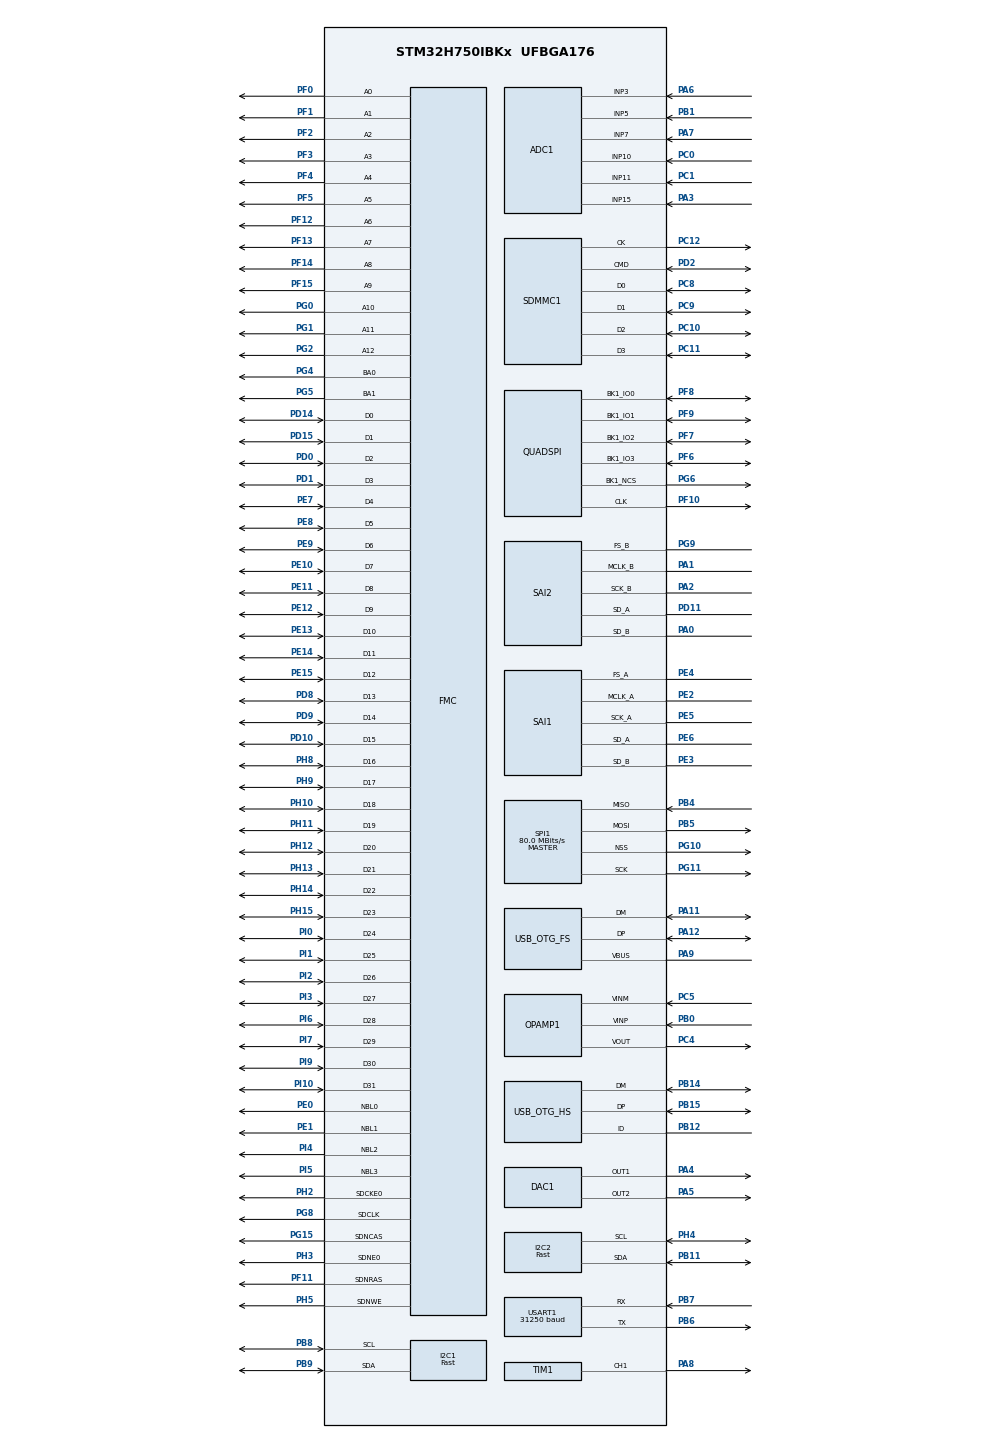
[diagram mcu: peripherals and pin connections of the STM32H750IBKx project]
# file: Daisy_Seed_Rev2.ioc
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ADC1.Channel-1\#ChannelRegularConversion=ADC_CHANNEL_3
ADC1.Channel-2\#ChannelRegularConversion=ADC_CHANNEL_4
ADC1.Channel-3\#ChannelRegularConversion=ADC_CHANNEL_7
ADC1.Channel-4\#ChannelRegularConversion=ADC_CHANNEL_10
ADC1.Channel-5\#ChannelRegularConversion=ADC_CHANNEL_11
ADC1.Channel-6\#ChannelRegularConversion=ADC_CHANNEL_15
ADC1.Channel-7\#ChannelRegularConversion=ADC_CHANNEL_15
ADC1.ClockPrescaler=ADC_CLOCK_ASYNC_DIV32
ADC1.ContinuousConvMode=ENABLE
ADC1.ConversionDataManagement=ADC_CONVERSIONDATA_DMA_CIRCULAR
ADC1.EOCSelection=ADC_EOC_SEQ_CONV
ADC1.NbrOfConversion=7
ADC1.NbrOfConversionFlag=1
ADC1.OffsetNumber-1\#ChannelRegularConversion=ADC_OFFSET_NONE
ADC1.OffsetNumber-2\#ChannelRegularConversion=ADC_OFFSET_NONE
ADC1.OffsetNumber-3\#ChannelRegularConversion=ADC_OFFSET_NONE
ADC1.OffsetNumber-4\#ChannelRegularConversion=ADC_OFFSET_NONE
ADC1.OffsetNumber-5\#ChannelRegularConversion=ADC_OFFSET_NONE
ADC1.OffsetNumber-6\#ChannelRegularConversion=ADC_OFFSET_NONE
ADC1.OffsetNumber-7\#ChannelRegularConversion=ADC_OFFSET_NONE
ADC1.Rank-1\#ChannelRegularConversion=1
ADC1.Rank-2\#ChannelRegularConversion=2
ADC1.Rank-3\#ChannelRegularConversion=3
ADC1.Rank-4\#ChannelRegularConversion=4
ADC1.Rank-5\#ChannelRegularConversion=5
ADC1.Rank-6\#ChannelRegularConversion=6
ADC1.Rank-7\#ChannelRegularConversion=7
ADC1.SamplingTime-1\#ChannelRegularConversion=ADC_SAMPLETIME_32CYCLES_5
ADC1.SamplingTime-2\#ChannelRegularConversion=ADC_SAMPLETIME_32CYCLES_5
ADC1.SamplingTime-3\#ChannelRegularConversion=ADC_SAMPLETIME_32CYCLES_5
ADC1.SamplingTime-4\#ChannelRegularConversion=ADC_SAMPLETIME_32CYCLES_5
ADC1.SamplingTime-5\#ChannelRegularConversion=ADC_SAMPLETIME_32CYCLES_5
ADC1.SamplingTime-6\#ChannelRegularConversion=ADC_SAMPLETIME_32CYCLES_5
ADC1.SamplingTime-7\#ChannelRegularConversion=ADC_SAMPLETIME_1CYCLE_5
ADC1.master=1
DAC1.DAC_Channel-DAC_OUT2=DAC_CHANNEL_2
DAC1.DAC_Trigger-DAC_OUT1=DAC_TRIGGER_SOFTWARE
DAC1.DAC_Trigger-DAC_OUT2=DAC_TRIGGER_SOFTWARE
Dma.ADC1.0.Direction=DMA_PERIPH_TO_MEMORY
Dma.ADC1.0.EventEnable=DISABLE
Dma.ADC1.0.FIFOMode=DMA_FIFOMODE_DISABLE
Dma.ADC1.0.Instance=DMA1_Stream0
Dma.ADC1.0.MemDataAlignment=DMA_MDATAALIGN_HALFWORD
Dma.ADC1.0.MemInc=DMA_MINC_ENABLE
Dma.ADC1.0.Mode=DMA_CIRCULAR
Dma.ADC1.0.PeriphDataAlignment=DMA_PDATAALIGN_HALFWORD
Dma.ADC1.0.PeriphInc=DMA_PINC_DISABLE
Dma.ADC1.0.Polarity=HAL_DMAMUX_REQ_GEN_RISING
Dma.ADC1.0.Priority=DMA_PRIORITY_LOW
Dma.ADC1.0.RequestNumber=1
Dma.ADC1.0.SignalID=NONE
Dma.ADC1.0.SyncEnable=DISABLE
Dma.ADC1.0.SyncPolarity=HAL_DMAMUX_SYNC_NO_EVENT
Dma.ADC1.0.SyncRequestNumber=1
Dma.ADC1.0.SyncSignalID=NONE
Dma.Request0=ADC1
Dma.Request1=SAI1_A
Dma.Request2=SAI1_B
Dma.Request3=SAI2_A
Dma.Request4=USART1_RX
Dma.Request5=SAI2_B
Dma.SAI1_A.1.Direction=DMA_PERIPH_TO_MEMORY
Dma.SAI1_A.1.EventEnable=ENABLE
Dma.SAI1_A.1.FIFOMode=DMA_FIFOMODE_DISABLE
Dma.SAI1_A.1.Instance=DMA1_Stream1
Dma.SAI1_A.1.MemDataAlignment=DMA_MDATAALIGN_WORD
Dma.SAI1_A.1.MemInc=DMA_MINC_ENABLE
Dma.SAI1_A.1.Mode=DMA_CIRCULAR
Dma.SAI1_A.1.PeriphDataAlignment=DMA_PDATAALIGN_WORD
Dma.SAI1_A.1.PeriphInc=DMA_PINC_DISABLE
Dma.SAI1_A.1.Polarity=HAL_DMAMUX_REQ_GEN_RISING
Dma.SAI1_A.1.Priority=DMA_PRIORITY_HIGH
Dma.SAI1_A.1.RequestNumber=1
Dma.SAI1_A.1.SignalID=NONE
Dma.SAI1_A.1.SyncEnable=ENABLE
Dma.SAI1_A.1.SyncPolarity=HAL_DMAMUX_SYNC_RISING
Dma.SAI1_A.1.SyncRequestNumber=1
Dma.SAI1_A.1.SyncSignalID=NONE
Dma.SAI1_B.2.Direction=DMA_MEMORY_TO_PERIPH
Dma.SAI1_B.2.EventEnable=DISABLE
Dma.SAI1_B.2.FIFOMode=DMA_FIFOMODE_DISABLE
Dma.SAI1_B.2.Instance=DMA1_Stream2
Dma.SAI1_B.2.MemDataAlignment=DMA_MDATAALIGN_WORD
Dma.SAI1_B.2.MemInc=DMA_MINC_ENABLE
Dma.SAI1_B.2.Mode=DMA_CIRCULAR
Dma.SAI1_B.2.PeriphDataAlignment=DMA_PDATAALIGN_WORD
Dma.SAI1_B.2.PeriphInc=DMA_PINC_DISABLE
Dma.SAI1_B.2.Polarity=HAL_DMAMUX_REQ_GEN_RISING
Dma.SAI1_B.2.Priority=DMA_PRIORITY_HIGH
Dma.SAI1_B.2.RequestNumber=1
Dma.SAI1_B.2.SignalID=NONE
Dma.SAI1_B.2.SyncEnable=DISABLE
Dma.SAI1_B.2.SyncPolarity=HAL_DMAMUX_SYNC_NO_EVENT
Dma.SAI1_B.2.SyncRequestNumber=1
Dma.SAI1_B.2.SyncSignalID=NONE
Dma.SAI2_A.3.Direction=DMA_PERIPH_TO_MEMORY
Dma.SAI2_A.3.EventEnable=DISABLE
Dma.SAI2_A.3.FIFOMode=DMA_FIFOMODE_DISABLE
Dma.SAI2_A.3.Instance=DMA1_Stream3
Dma.SAI2_A.3.MemDataAlignment=DMA_MDATAALIGN_WORD
Dma.SAI2_A.3.MemInc=DMA_MINC_ENABLE
Dma.SAI2_A.3.Mode=DMA_CIRCULAR
Dma.SAI2_A.3.PeriphDataAlignment=DMA_PDATAALIGN_WORD
Dma.SAI2_A.3.PeriphInc=DMA_PINC_DISABLE
Dma.SAI2_A.3.Polarity=HAL_DMAMUX_REQ_GEN_RISING
Dma.SAI2_A.3.Priority=DMA_PRIORITY_HIGH
Dma.SAI2_A.3.RequestNumber=1
Dma.SAI2_A.3.SignalID=NONE
Dma.SAI2_A.3.SyncEnable=ENABLE
Dma.SAI2_A.3.SyncPolarity=HAL_DMAMUX_SYNC_RISING
Dma.SAI2_A.3.SyncRequestNumber=1
Dma.SAI2_A.3.SyncSignalID=HAL_DMAMUX1_SYNC_DMAMUX1_CH1_EVT
Dma.SAI2_B.5.Direction=DMA_MEMORY_TO_PERIPH
Dma.SAI2_B.5.EventEnable=DISABLE
Dma.SAI2_B.5.FIFOMode=DMA_FIFOMODE_DISABLE
Dma.SAI2_B.5.Instance=DMA1_Stream4
Dma.SAI2_B.5.MemDataAlignment=DMA_MDATAALIGN_WORD
Dma.SAI2_B.5.MemInc=DMA_MINC_ENABLE
Dma.SAI2_B.5.Mode=DMA_CIRCULAR
Dma.SAI2_B.5.PeriphDataAlignment=DMA_PDATAALIGN_WORD
Dma.SAI2_B.5.PeriphInc=DMA_PINC_DISABLE
Dma.SAI2_B.5.Polarity=HAL_DMAMUX_REQ_GEN_RISING
Dma.SAI2_B.5.Priority=DMA_PRIORITY_HIGH
Dma.SAI2_B.5.RequestNumber=1
Dma.SAI2_B.5.SignalID=NONE
Dma.SAI2_B.5.SyncEnable=ENABLE
Dma.SAI2_B.5.SyncPolarity=HAL_DMAMUX_SYNC_RISING
Dma.SAI2_B.5.SyncRequestNumber=1
Dma.SAI2_B.5.SyncSignalID=HAL_DMAMUX1_SYNC_DMAMUX1_CH1_EVT
Dma.USART1_RX.4.Direction=DMA_PERIPH_TO_MEMORY
Dma.USART1_RX.4.EventEnable=DISABLE
Dma.USART1_RX.4.FIFOMode=DMA_FIFOMODE_DISABLE
Dma.USART1_RX.4.Instance=DMA1_Stream5
Dma.USART1_RX.4.MemDataAlignment=DMA_MDATAALIGN_BYTE
Dma.USART1_RX.4.MemInc=DMA_MINC_ENABLE
Dma.USART1_RX.4.Mode=DMA_CIRCULAR
Dma.USART1_RX.4.PeriphDataAlignment=DMA_PDATAALIGN_BYTE
Dma.USART1_RX.4.PeriphInc=DMA_PINC_DISABLE
Dma.USART1_RX.4.Polarity=HAL_DMAMUX_REQ_GEN_RISING
Dma.USART1_RX.4.Priority=DMA_PRIORITY_LOW
Dma.USART1_RX.4.RequestNumber=1
Dma.USART1_RX.4.SignalID=NONE
Dma.USART1_RX.4.SyncEnable=DISABLE
Dma.USART1_RX.4.SyncPolarity=HAL_DMAMUX_SYNC_NO_EVENT
Dma.USART1_RX.4.SyncRequestNumber=1
Dma.USART1_RX.4.SyncSignalID=NONE
FATFS.USE_DMA_CODE_SD=0
FATFS._FS_NORTC=0
FATFS._USE_LFN=1
I2C1.I2C_Rise_Time=300
I2C1.I2C_Speed_Mode=I2C_Fast
I2C1.Timing=0x30B00F2D
I2C2.I2C_Speed_Mode=I2C_Fast
I2C2.Timing=0x00B03FDB
Mcu.Family=STM32H7
Mcu.Name=STM32H750IBKx
Mcu.Package=UFBGA176
NVIC.DMA1_Stream0_IRQn=true\:0\:0\:false\:false\:true\:false\:true
NVIC.DMA1_Stream1_IRQn=true\:0\:0\:false\:false\:true\:false\:true
NVIC.DMA1_Stream2_IRQn=true\:0\:0\:false\:false\:true\:false\:true
NVIC.DMA1_Stream3_IRQn=true\:0\:0\:false\:false\:true\:false\:true
NVIC.DMA1_Stream4_IRQn=true\:0\:0\:false\:false\:true\:false\:true
NVIC.DMA1_Stream5_IRQn=true\:0\:0\:false\:false\:true\:false\:true
NVIC.DMAMUX1_OVR_IRQn=true\:0\:0\:false\:false\:true\:false\:true
NVIC.OTG_FS_EP1_IN_IRQn=true\:0\:0\:false\:false\:true\:true\:true
NVIC.OTG_FS_EP1_OUT_IRQn=true\:0\:0\:false\:false\:true\:true\:true
NVIC.OTG_FS_IRQn=true\:0\:0\:false\:false\:true\:true\:true
NVIC.PriorityGroup=NVIC_PRIORITYGROUP_4
NVIC.SDMMC1_IRQn=true\:0\:0\:false\:false\:true\:true\:true
NVIC.USART1_IRQn=true\:0\:0\:false\:false\:true\:true\:true
PA0.Mode=SAI_B_MasterWithClock
PA0.Signal=SAI2_SD_B
PA1.Mode=SAI_B_MasterWithClock
PA1.Signal=SAI2_MCLK_B
PA11.Mode=Device_Only
PA11.Signal=USB_OTG_FS_DM
PA12.Mode=Device_Only
PA12.Signal=USB_OTG_FS_DP
PA13\ (JTMS/SWDIO).Mode=JTAG_4_pins
PA13\ (JTMS/SWDIO).Signal=DEBUG_JTMS-SWDIO
PA14\ (JTCK/SWCLK).Mode=JTAG_4_pins
PA14\ (JTCK/SWCLK).Signal=DEBUG_JTCK-SWCLK
PA15\ (JTDI).Mode=JTAG_4_pins
PA15\ (JTDI).Signal=DEBUG_JTDI
PA2.Mode=SAI_B_MasterWithClock
PA2.Signal=SAI2_SCK_B
PA3.Signal=ADCx_INP15
PA4.Signal=COMP_DAC11_group
PA5.Signal=COMP_DAC12_group
PA6.Signal=ADCx_INP3
PA7.Signal=ADCx_INP7
PA8.Signal=S_TIM1_CH1
PA9.Mode=Activate_VBUS
PA9.Signal=USB_OTG_FS_VBUS
PB0.Mode=PGA Connected-INVERTINGINPUT_IO0
PB0.Signal=OPAMP1_VINP
PB1.Signal=ADCx_INP5
PB11.Mode=I2C
PB11.Signal=I2C2_SDA
PB12.Mode=OTG/Dual-Role-Device-FS
PB12.Signal=USB_OTG_HS_ID
PB14.Mode=OTG/Dual-Role-Device-FS
PB14.Signal=USB_OTG_HS_DM
PB15.Mode=OTG/Dual-Role-Device-FS
PB15.Signal=USB_OTG_HS_DP
PB3\ (JTDO/TRACESWO).Mode=JTAG_4_pins
PB3\ (JTDO/TRACESWO).Signal=DEBUG_JTDO-SWO
PB4\ (NJTRST).Mode=Full_Duplex_Master
PB4\ (NJTRST).Signal=SPI1_MISO
PB5.Mode=Full_Duplex_Master
PB5.Signal=SPI1_MOSI
PB6.Mode=Asynchronous
PB6.Signal=USART1_TX
PB7.Mode=Asynchronous
PB7.Signal=USART1_RX
PB8.Mode=I2C
PB8.Signal=I2C1_SCL
PB9.Mode=I2C
PB9.Signal=I2C1_SDA
PC0.Signal=ADCx_INP10
PC1.Signal=ADCx_INP11
PC10.Mode=SD_4_bits_Wide_bus
PC10.Signal=SDMMC1_D2
PC11.Mode=SD_4_bits_Wide_bus
PC11.Signal=SDMMC1_D3
PC12.Mode=SD_4_bits_Wide_bus
PC12.Signal=SDMMC1_CK
PC4.Mode=PGA Connected-INVERTINGINPUT_IO0
PC4.Signal=OPAMP1_VOUT
PC5.Mode=PGA Connected-INVERTINGINPUT_IO0
PC5.Signal=OPAMP1_VINM
PC8.Mode=SD_4_bits_Wide_bus
PC8.Signal=SDMMC1_D0
PC9.Mode=SD_4_bits_Wide_bus
PC9.Signal=SDMMC1_D1
PD0.Signal=FMC_D2_DA2
PD1.Signal=FMC_D3_DA3
PD10.Signal=FMC_D15_DA15
PD11.Mode=SAI_A_SyncSlave
PD11.Signal=SAI2_SD_A
PD14.Signal=FMC_D0_DA0
PD15.Signal=FMC_D1_DA1
PD2.Mode=SD_4_bits_Wide_bus
PD2.Signal=SDMMC1_CMD
PD8.Signal=FMC_D13_DA13
PD9.Signal=FMC_D14_DA14
PE0.Signal=FMC_NBL0
PE1.Signal=FMC_NBL1
PE10.Signal=FMC_D7_DA7
PE11.Signal=FMC_D8_DA8
PE12.Signal=FMC_D9_DA9
PE13.Signal=FMC_D10_DA10
PE14.Signal=FMC_D11_DA11
PE15.Signal=FMC_D12_DA12
PE2.Mode=SAI_A_MasterWithClock
PE2.Signal=SAI1_MCLK_A
PE3.Mode=SAI_B_SyncSlave
PE3.Signal=SAI1_SD_B
PE4.Mode=SAI_A_MasterWithClock
PE4.Signal=SAI1_FS_A
PE5.Mode=SAI_A_MasterWithClock
PE5.Signal=SAI1_SCK_A
PE6.Mode=SAI_A_MasterWithClock
PE6.Signal=SAI1_SD_A
PE7.Signal=FMC_D4_DA4
PE8.Signal=FMC_D5_DA5
PE9.Signal=FMC_D6_DA6
PF0.Signal=FMC_A0
PF1.Signal=FMC_A1
PF10.Mode=Single Bank 1
PF10.Signal=QUADSPI_CLK
PF11.Signal=FMC_SDNRAS
PF12.Signal=FMC_A6
PF13.Signal=FMC_A7
PF14.Signal=FMC_A8
PF15.Signal=FMC_A9
PF2.Signal=FMC_A2
PF3.Signal=FMC_A3
PF4.Signal=FMC_A4
PF5.Signal=FMC_A5
PF6.Mode=Single Bank 1
PF6.Signal=QUADSPI_BK1_IO3
PF7.Mode=Single Bank 1
PF7.Signal=QUADSPI_BK1_IO2
PF8.Mode=Single Bank 1
PF8.Signal=QUADSPI_BK1_IO0
PF9.Mode=Single Bank 1
PF9.Signal=QUADSPI_BK1_IO1
PG0.Signal=FMC_A10
PG1.Signal=FMC_A11
PG10.Mode=NSS_Signal_Hard_Output
PG10.Signal=SPI1_NSS
PG11.Mode=Full_Duplex_Master
PG11.Signal=SPI1_SCK
PG15.Signal=FMC_SDNCAS
PG2.Signal=FMC_A12
PG4.Signal=FMC_A14_BA0
PG5.Signal=FMC_A15_BA1
PG6.Mode=Single Bank 1
PG6.Signal=QUADSPI_BK1_NCS
PG8.Signal=FMC_SDCLK
PG9.Mode=SAI_B_MasterWithClock
PG9.Signal=SAI2_FS_B
PH0-OSC_IN\ (PH0).Mode=HSE-External-Oscillator
PH0-OSC_IN\ (PH0).Signal=RCC_OSC_IN
PH1-OSC_OUT\ (PH1).Mode=HSE-External-Oscillator
PH1-OSC_OUT\ (PH1).Signal=RCC_OSC_OUT
PH10.Signal=FMC_D18
PH11.Signal=FMC_D19
PH12.Signal=FMC_D20
PH13.Signal=FMC_D21
PH14.Signal=FMC_D22
PH15.Signal=FMC_D23
PH2.Mode=SdramChipSelect1_1
PH2.Signal=FMC_SDCKE0
PH3.Mode=SdramChipSelect1_1
PH3.Signal=FMC_SDNE0
PH4.Mode=I2C
PH4.Signal=I2C2_SCL
PH5.Signal=FMC_SDNWE
PH8.Signal=FMC_D16
PH9.Signal=FMC_D17
PI0.Signal=FMC_D24
PI1.Signal=FMC_D25
PI10.Signal=FMC_D31
PI2.Signal=FMC_D26
PI3.Signal=FMC_D27
PI4.Signal=FMC_NBL2
PI5.Signal=FMC_NBL3
PI6.Signal=FMC_D28
PI7.Signal=FMC_D29
PI9.Signal=FMC_D30
ProjectManager.HeapSize=0x2000
ProjectManager.StackSize=0x4000
ProjectManager.TargetToolchain=Other Toolchains (GPDSC)
QUADSPI.ClockPrescaler=1
QUADSPI.FlashSize=19
RCC.ADCCLockSelection=RCC_ADCCLKSOURCE_PLL3
RCC.ADCFreq_Value=12288085.9375
RCC.APB1Freq_Value=120000000
RCC.APB2Freq_Value=120000000
RCC.APB3Freq_Value=120000000
RCC.APB4Freq_Value=120000000
RCC.CKPERSourceSelection=RCC_CLKPSOURCE_HSE
RCC.CortexFreq_Value=480000000
RCC.D1PPRE=RCC_APB3_DIV2
RCC.D2PPRE1=RCC_APB1_DIV2
RCC.D2PPRE2=RCC_APB2_DIV2
RCC.D3PPRE=RCC_APB4_DIV2
RCC.DIVM1=1
RCC.DIVM2=1
RCC.DIVM3=1
RCC.DIVN1=60
RCC.DIVN2=12
RCC.DIVN3=12
RCC.DIVP2=8
RCC.DIVP3=4
RCC.DIVQ1=6
RCC.DIVQ3=8
RCC.DIVR1=8
RCC.DIVR3=16
RCC.FMCCLockSelection=RCC_FMCCLKSOURCE_PLL2
RCC.HCLKFreq_Value=240000000
RCC.HPRE=RCC_HCLK_DIV2
RCC.HSE_VALUE=16000000
RCC.PLL2FRACN=4096
RCC.PLL3FRACN=2360
RCC.PLLFRACN=0
RCC.PLLSourceVirtual=RCC_PLLSOURCE_HSE
RCC.QSPICLockSelection=RCC_QSPICLKSOURCE_PLL
RCC.SAI1CLockSelection=RCC_SAI1CLKSOURCE_PLL3
RCC.SAI23CLockSelection=RCC_SAI23CLKSOURCE_PLL3
RCC.SDMMC1CLockSelection=RCC_SDMMCCLKSOURCE_PLL2
RCC.SYSCLKFreq_VALUE=480000000
RCC.SYSCLKSource=RCC_SYSCLKSOURCE_PLLCLK
RCC.USBCLockSelection=RCC_USBCLKSOURCE_HSI48
RCC.USBFreq_Value=48000000
SAI1.AudioFrequency-SAI_A_MasterWithClock=SAI_AUDIO_FREQUENCY_48K
SAI1.AudioMode-SAI_A_MasterWithClock=SAI_MODEMASTER_RX
SAI1.AudioMode-SAI_B_SyncSlave=SAI_MODESLAVE_TX
SAI1.BasicDataSize-SAI_A_MasterWithClock=SAI_PROTOCOL_DATASIZE_24BIT
SAI1.BasicDataSize-SAI_B_SyncSlave=SAI_PROTOCOL_DATASIZE_24BIT
SAI1.BasicProtocol-SAI_A_MasterWithClock=SAI_I2S_MSBJUSTIFIED
SAI1.BasicProtocol-SAI_B_SyncSlave=SAI_I2S_MSBJUSTIFIED
SAI1.ErrorAudioFreq-SAI_A_MasterWithClock=0.0 %
SAI1.InitProtocol-SAI_A_MasterWithClock=Enable
SAI1.InitProtocol-SAI_B_SyncSlave=Enable
SAI1.Instance-SAI_A_MasterWithClock=SAI$Index_Block_A
SAI1.Instance-SAI_B_SyncSlave=SAI$Index_Block_B
SAI1.MClockEnable-SAI_A_MasterWithClock=SAI_MASTERCLOCK_ENABLE
SAI1.RealAudioFreq-SAI_A_MasterWithClock=48.0 KHz
SAI1.VirtualMode-SAI_A_MasterWithClock=VM_MASTER
SAI1.VirtualMode-SAI_B_SyncSlave=VM_SLAVE
SAI1.VirtualProtocol-SAI_A_BASIC=VM_BASIC_PROTOCOL
SAI1.VirtualProtocol-SAI_B_BASIC=VM_BASIC_PROTOCOL
SAI2.AudioFrequency-SAI_B_MasterWithClock=SAI_AUDIO_FREQUENCY_192K
SAI2.ErrorAudioFreq-SAI_B_MasterWithClock=0.0 %
SAI2.InitProtocol-SAI_A_SyncSlave=Enable
SAI2.InitProtocol-SAI_B_MasterWithClock=Enable
SAI2.Instance-SAI_A_SyncSlave=SAI$Index_Block_A
SAI2.Instance-SAI_B_MasterWithClock=SAI$Index_Block_B
SAI2.MClockEnable-SAI_B_MasterWithClock=SAI_MASTERCLOCK_ENABLE
SAI2.RealAudioFreq-SAI_B_MasterWithClock=192.001 KHz
SAI2.Synchro_A=SAI_SYNCHRONOUS
SAI2.VirtualMode-SAI_A_SyncSlave=VM_SLAVE
SAI2.VirtualMode-SAI_B_MasterWithClock=VM_MASTER
SAI2.VirtualProtocol-SAI_A_BASIC=VM_BASIC_PROTOCOL
SAI2.VirtualProtocol-SAI_B_BASIC=VM_BASIC_PROTOCOL
SDMMC1.ClockDiv=168
SDMMC1.USE_SD_TRANSCEIVER=0U
SH.ADCx_INP10.0=ADC1_INP10,IN10-Single-Ended
SH.ADCx_INP11.0=ADC1_INP11,IN11-Single-Ended
SH.ADCx_INP15.0=ADC1_INP15,IN15-Single-Ended
SH.ADCx_INP3.0=ADC1_INP3,IN3-Single-Ended
SH.ADCx_INP5.0=ADC1_INP5,IN5-Single-Ended
SH.ADCx_INP7.0=ADC1_INP7,IN7-Single-Ended
SH.COMP_DAC11_group.0=DAC1_OUT1,DAC_OUT1
SH.COMP_DAC12_group.0=DAC1_OUT2,DAC_OUT2
SH.FMC_A0.0=FMC_A0,13b-sda1
SH.FMC_A1.0=FMC_A1,13b-sda1
SH.FMC_A10.0=FMC_A10,13b-sda1
SH.FMC_A11.0=FMC_A11,13b-sda1
SH.FMC_A12.0=FMC_A12,13b-sda1
SH.FMC_A14_BA0.0=FMC_BA0,FourSdramBanks1
SH.FMC_A15_BA1.0=FMC_BA1,FourSdramBanks1
SH.FMC_A2.0=FMC_A2,13b-sda1
SH.FMC_A3.0=FMC_A3,13b-sda1
SH.FMC_A4.0=FMC_A4,13b-sda1
SH.FMC_A5.0=FMC_A5,13b-sda1
SH.FMC_A6.0=FMC_A6,13b-sda1
SH.FMC_A7.0=FMC_A7,13b-sda1
SH.FMC_A8.0=FMC_A8,13b-sda1
SH.FMC_A9.0=FMC_A9,13b-sda1
SH.FMC_D0_DA0.0=FMC_D0,sd-32b-d1
SH.FMC_D10_DA10.0=FMC_D10,sd-32b-d1
SH.FMC_D11_DA11.0=FMC_D11,sd-32b-d1
SH.FMC_D12_DA12.0=FMC_D12,sd-32b-d1
SH.FMC_D13_DA13.0=FMC_D13,sd-32b-d1
SH.FMC_D14_DA14.0=FMC_D14,sd-32b-d1
SH.FMC_D15_DA15.0=FMC_D15,sd-32b-d1
SH.FMC_D16.0=FMC_D16,sd-32b-d1
SH.FMC_D17.0=FMC_D17,sd-32b-d1
SH.FMC_D18.0=FMC_D18,sd-32b-d1
SH.FMC_D19.0=FMC_D19,sd-32b-d1
SH.FMC_D1_DA1.0=FMC_D1,sd-32b-d1
SH.FMC_D20.0=FMC_D20,sd-32b-d1
SH.FMC_D21.0=FMC_D21,sd-32b-d1
SH.FMC_D22.0=FMC_D22,sd-32b-d1
SH.FMC_D23.0=FMC_D23,sd-32b-d1
SH.FMC_D24.0=FMC_D24,sd-32b-d1
SH.FMC_D25.0=FMC_D25,sd-32b-d1
SH.FMC_D26.0=FMC_D26,sd-32b-d1
SH.FMC_D27.0=FMC_D27,sd-32b-d1
SH.FMC_D28.0=FMC_D28,sd-32b-d1
SH.FMC_D29.0=FMC_D29,sd-32b-d1
SH.FMC_D2_DA2.0=FMC_D2,sd-32b-d1
SH.FMC_D30.0=FMC_D30,sd-32b-d1
SH.FMC_D31.0=FMC_D31,sd-32b-d1
SH.FMC_D3_DA3.0=FMC_D3,sd-32b-d1
SH.FMC_D4_DA4.0=FMC_D4,sd-32b-d1
SH.FMC_D5_DA5.0=FMC_D5,sd-32b-d1
SH.FMC_D6_DA6.0=FMC_D6,sd-32b-d1
SH.FMC_D7_DA7.0=FMC_D7,sd-32b-d1
SH.FMC_D8_DA8.0=FMC_D8,sd-32b-d1
SH.FMC_D9_DA9.0=FMC_D9,sd-32b-d1
SH.FMC_NBL0.0=FMC_NBL0,Sd4ByteEnable1
SH.FMC_NBL1.0=FMC_NBL1,Sd4ByteEnable1
SH.FMC_NBL2.0=FMC_NBL2,Sd4ByteEnable1
SH.FMC_NBL3.0=FMC_NBL3,Sd4ByteEnable1
SH.FMC_SDCLK.0=FMC_SDCLK,13b-sda1
SH.FMC_SDNCAS.0=FMC_SDNCAS,13b-sda1
SH.FMC_SDNRAS.0=FMC_SDNRAS,13b-sda1
SH.FMC_SDNWE.0=FMC_SDNWE,13b-sda1
SH.S_TIM1_CH1.0=TIM1_CH1,Output Compare1 CH1
SPI1.BaudRatePrescaler=SPI_BAUDRATEPRESCALER_2
SPI1.CalculateBaudRate=80.0 MBits/s
SPI1.Direction=SPI_DIRECTION_2LINES
SPI1.Mode=SPI_MODE_MASTER
SPI1.VirtualNSS=VM_NSSHARD
SPI1.VirtualType=VM_MASTER
TIM1.Channel-Output\ Compare1\ CH1=TIM_CHANNEL_1
USART1.BaudRate=31250
USART1.VirtualMode-Asynchronous=VM_ASYNC
USB_DEVICE.CLASS_NAME_FS=CDC
USB_DEVICE.VirtualMode-CDC_FS=Cdc
USB_DEVICE.VirtualModeFS=Cdc_FS
USB_OTG_FS.VirtualMode=Device_Only
USB_OTG_FS.battery_charging_enable=DISABLE
VP_ADC1_OPAMP1_OUT.Mode=IN4-OPAMP1-Single-Ended
VP_FATFS_VS_SDIO.Mode=SDIO
VP_RNG_VS_RNG.Mode=RNG_Activate
VP_SAI1_VP_$IpInstance_SAIA_SAI_BASIC.Mode=SAI_A_BASIC
VP_SAI1_VP_$IpInstance_SAIB_SAI_BASIC.Mode=SAI_B_BASIC
VP_SAI2_VP_$IpInstance_SAIA_SAI_BASIC.Mode=SAI_A_BASIC
VP_SAI2_VP_$IpInstance_SAIB_SAI_BASIC.Mode=SAI_B_BASIC
VP_USB_DEVICE_VS_USB_DEVICE_CDC_FS.Mode=CDC_FS
board=custom

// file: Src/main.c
/* USER CODE BEGIN Header */
/**
  ******************************************************************************
  * @file           : main.c
  * @brief          : Main program body
  ******************************************************************************
  * @attention
  *
  * <h2><center>&copy; Copyright (c) 2019 STMicroelectronics.
  * All rights reserved.</center></h2>
  *
  * This software component is licensed by ST under Ultimate Liberty license
  * SLA0044, the "License"; You may not use this file except in compliance with
  * the License. You may obtain a copy of the License at:
  *                             www.st.com/SLA0044
  *
  ******************************************************************************
  */
/* USER CODE END Header */

#include "main.h"
#include "adc.h"
#include "dac.h"
#include "dma.h"
#include "fatfs.h"
#include "i2c.h"
#include "opamp.h"
#include "quadspi.h"
#include "rng.h"
#include "sai.h"
#include "sdmmc.h"
#include "spi.h"
#include "tim.h"
#include "usart.h"
#include "usb_device.h"
#include "usb_otg_hs.h"
#include "gpio.h"
#include "fmc.h"

/* USER CODE BEGIN Includes */
#include <string.h>
#include "usbd_cdc_if.h"

/* USER CODE END Includes */

/* USER CODE BEGIN PV */
uint8_t mybuff[32];

/* USER CODE END PV */

void SystemClock_Config(void);
/* USER CODE BEGIN PFP */
void CheckClockFreq();

/* USER CODE END PFP */

int main(void)
{

  /* MCU Configuration--------------------------------------------------------*/

  /* Reset of all peripherals, Initializes the Flash interface and the Systick. */
  HAL_Init();

  /* Configure the system clock */
  SystemClock_Config();

  /* USER CODE BEGIN SysInit */
    CheckClockFreq();

  /* USER CODE END SysInit */

  /* Initialize all configured peripherals */
  MX_GPIO_Init();
  MX_DMA_Init();
  MX_ADC1_Init();
  MX_DAC1_Init();
  MX_FMC_Init();
  MX_I2C2_Init();
  MX_OPAMP1_Init();
  MX_QUADSPI_Init();
  MX_SAI1_Init();
  MX_SAI2_Init();
  MX_SDMMC1_SD_Init();
  MX_SPI1_Init();
  MX_TIM1_Init();
  MX_USART1_UART_Init();
  MX_I2C1_Init();
  MX_RNG_Init();
  MX_FATFS_Init();
  MX_USB_OTG_HS_USB_Init();
  MX_USB_DEVICE_Init();
  /* USER CODE BEGIN 2 */
    //    uint8_t buff[512];
    //    uint8_t check_buff[512];
    //    for(size_t i = 0; i < 512; i++)
    //    {
    //        buff[i]       = (uint8_t)(i & 0xff);
    //        check_buff[i] = 0;
    //    }
    //
    //    uint8_t status;
    //    size_t  byteswritten;
    //    if(f_mount(&SDFatFS, SDPath, 1) == FR_OK)
    //    {
    //        FIL f;
    //        if(f_open(&f, "myfile.bin", (FA_CREATE_ALWAYS | FA_WRITE)) == FR_OK)
    //        {
    //            f_write(&f, buff, 512, &byteswritten);
    //            f_close(&f);
    //        }
    //        if(f_open(&f, "myfile.bin", (FA_READ)) == FR_OK)
    //        {
    //            f_read(&f, check_buff, 512, &byteswritten);
    //            f_close(&f);
    //        }
    //    }
    //    // Check
    //    size_t fail_cnt;
    //    fail_cnt = 0;
    //    for(size_t i = 0; i < 512; i++)
    //    {
    //        if(check_buff[i] != buff[i])
    //        {
    //            fail_cnt += 1;
    //        }
    //    }
    //    if(fail_cnt)
    //    {
    //        asm("bkpt 255");
    //    }
  /* USER CODE END 2 */

  /* Infinite loop */
    while(1)
    {

    }
}

void SystemClock_Config(void)
{
  RCC_OscInitTypeDef RCC_OscInitStruct = {0};
  RCC_ClkInitTypeDef RCC_ClkInitStruct = {0};
  RCC_PeriphCLKInitTypeDef PeriphClkInitStruct = {0};

  /** Supply configuration update enable
  */
  HAL_PWREx_ConfigSupply(PWR_LDO_SUPPLY);
  /** Configure the main internal regulator output voltage
  */
  __HAL_PWR_VOLTAGESCALING_CONFIG(PWR_REGULATOR_VOLTAGE_SCALE0);

  while(!__HAL_PWR_GET_FLAG(PWR_FLAG_VOSRDY)) {}
  /** Macro to configure the PLL clock source
  */
  __HAL_RCC_PLL_PLLSOURCE_CONFIG(RCC_PLLSOURCE_HSE);
  /** Initializes the CPU, AHB and APB busses clocks
  */
  RCC_OscInitStruct.OscillatorType = RCC_OSCILLATORTYPE_HSI48|RCC_OSCILLATORTYPE_HSE;
  RCC_OscInitStruct.HSEState = RCC_HSE_ON;
  RCC_OscInitStruct.HSI48State = RCC_HSI48_ON;
  RCC_OscInitStruct.PLL.PLLState = RCC_PLL_ON;
  RCC_OscInitStruct.PLL.PLLSource = RCC_PLLSOURCE_HSE;
  RCC_OscInitStruct.PLL.PLLM = 1;
  RCC_OscInitStruct.PLL.PLLN = 60;
  RCC_OscInitStruct.PLL.PLLP = 2;
  RCC_OscInitStruct.PLL.PLLQ = 6;
  RCC_OscInitStruct.PLL.PLLR = 8;
  RCC_OscInitStruct.PLL.PLLRGE = RCC_PLL1VCIRANGE_3;
  RCC_OscInitStruct.PLL.PLLVCOSEL = RCC_PLL1VCOWIDE;
  RCC_OscInitStruct.PLL.PLLFRACN = 0;
  if (HAL_RCC_OscConfig(&RCC_OscInitStruct) != HAL_OK)
  {
    Error_Handler();
  }
  /** Initializes the CPU, AHB and APB busses clocks
  */
  RCC_ClkInitStruct.ClockType = RCC_CLOCKTYPE_HCLK|RCC_CLOCKTYPE_SYSCLK
                              |RCC_CLOCKTYPE_PCLK1|RCC_CLOCKTYPE_PCLK2
                              |RCC_CLOCKTYPE_D3PCLK1|RCC_CLOCKTYPE_D1PCLK1;
  RCC_ClkInitStruct.SYSCLKSource = RCC_SYSCLKSOURCE_PLLCLK;
  RCC_ClkInitStruct.SYSCLKDivider = RCC_SYSCLK_DIV1;
  RCC_ClkInitStruct.AHBCLKDivider = RCC_HCLK_DIV2;
  RCC_ClkInitStruct.APB3CLKDivider = RCC_APB3_DIV2;
  RCC_ClkInitStruct.APB1CLKDivider = RCC_APB1_DIV2;
  RCC_ClkInitStruct.APB2CLKDivider = RCC_APB2_DIV2;
  RCC_ClkInitStruct.APB4CLKDivider = RCC_APB4_DIV2;

  if (HAL_RCC_ClockConfig(&RCC_ClkInitStruct, FLASH_LATENCY_4) != HAL_OK)
  {
    Error_Handler();
  }
  PeriphClkInitStruct.PeriphClockSelection = RCC_PERIPHCLK_USART1|RCC_PERIPHCLK_RNG
                              |RCC_PERIPHCLK_SPI1|RCC_PERIPHCLK_SAI2
                              |RCC_PERIPHCLK_SAI1|RCC_PERIPHCLK_SDMMC
                              |RCC_PERIPHCLK_I2C2|RCC_PERIPHCLK_ADC
                              |RCC_PERIPHCLK_I2C1|RCC_PERIPHCLK_USB
                              |RCC_PERIPHCLK_QSPI|RCC_PERIPHCLK_FMC;
  PeriphClkInitStruct.PLL2.PLL2M = 1;
  PeriphClkInitStruct.PLL2.PLL2N = 12;
  PeriphClkInitStruct.PLL2.PLL2P = 8;
  PeriphClkInitStruct.PLL2.PLL2Q = 2;
  PeriphClkInitStruct.PLL2.PLL2R = 2;
  PeriphClkInitStruct.PLL2.PLL2RGE = RCC_PLL2VCIRANGE_3;
  PeriphClkInitStruct.PLL2.PLL2VCOSEL = RCC_PLL2VCOWIDE;
  PeriphClkInitStruct.PLL2.PLL2FRACN = 4096;
  PeriphClkInitStruct.PLL3.PLL3M = 1;
  PeriphClkInitStruct.PLL3.PLL3N = 12;
  PeriphClkInitStruct.PLL3.PLL3P = 4;
  PeriphClkInitStruct.PLL3.PLL3Q = 8;
  PeriphClkInitStruct.PLL3.PLL3R = 16;
  PeriphClkInitStruct.PLL3.PLL3RGE = RCC_PLL3VCIRANGE_3;
  PeriphClkInitStruct.PLL3.PLL3VCOSEL = RCC_PLL3VCOWIDE;
  PeriphClkInitStruct.PLL3.PLL3FRACN = 2360;
  PeriphClkInitStruct.FmcClockSelection = RCC_FMCCLKSOURCE_PLL2;
  PeriphClkInitStruct.QspiClockSelection = RCC_QSPICLKSOURCE_PLL;
  PeriphClkInitStruct.SdmmcClockSelection = RCC_SDMMCCLKSOURCE_PLL2;
  PeriphClkInitStruct.Sai1ClockSelection = RCC_SAI1CLKSOURCE_PLL3;
  PeriphClkInitStruct.Sai23ClockSelection = RCC_SAI23CLKSOURCE_PLL3;
  PeriphClkInitStruct.Spi123ClockSelection = RCC_SPI123CLKSOURCE_PLL;
  PeriphClkInitStruct.Usart16ClockSelection = RCC_USART16CLKSOURCE_D2PCLK2;
  PeriphClkInitStruct.RngClockSelection = RCC_RNGCLKSOURCE_HSI48;
  PeriphClkInitStruct.I2c123ClockSelection = RCC_I2C123CLKSOURCE_D2PCLK1;
  PeriphClkInitStruct.UsbClockSelection = RCC_USBCLKSOURCE_HSI48;
  PeriphClkInitStruct.AdcClockSelection = RCC_ADCCLKSOURCE_PLL3;
  if (HAL_RCCEx_PeriphCLKConfig(&PeriphClkInitStruct) != HAL_OK)
  {
    Error_Handler();
  }
  /** Enable USB Voltage detector
  */
  HAL_PWREx_EnableUSBVoltageDetector();
}

/* USER CODE BEGIN 4 */

void CheckClockFreq()
{
    PLL1_ClocksTypeDef clk1;
    PLL2_ClocksTypeDef clk2;
    PLL3_ClocksTypeDef clk3;
    HAL_RCCEx_GetPLL1ClockFreq(&clk1);
    HAL_RCCEx_GetPLL2ClockFreq(&clk2);
    HAL_RCCEx_GetPLL3ClockFreq(&clk3);
    if(clk3.PLL3_R_Frequency != 12288818)
    {
        __asm("bkpt 255");
    }
}

/* USER CODE END 4 */

void Error_Handler(void)
{
}

/************************ (C) COPYRIGHT STMicroelectronics *****END OF FILE****/
